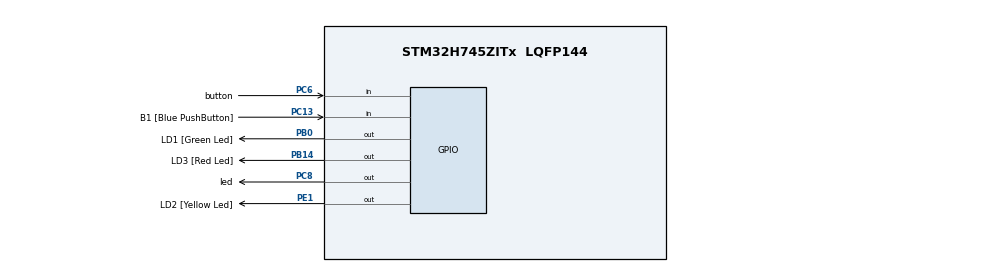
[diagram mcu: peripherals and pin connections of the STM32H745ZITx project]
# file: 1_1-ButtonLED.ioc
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CORTEX_M7.default_mode_Activation=1
CortexM4.IPs=FATFS_M4\:I,FREERTOS_M4\:I,IWDG2\:I,RCC,WWDG2\:I,DMA,BDMA,MDMA,NVIC2\:I,USART3,ETH,DEBUG,PDM2PCM_M4\:I,PWR,RESMGR_UTILITY,SYS_M4\:I,USB_DEVICE_M4\:I,USB_HOST_M4\:I,CORTEX_M4\:I,GPIO,OPENAMP_M4\:I,VREFBUF,NUCLEO-H745ZI-Q\:I
CortexM7.IPs=FATFS_M7\:I,FREERTOS_M7\:I,IWDG1\:I,RCC\:I,WWDG1\:I,DMA\:I,BDMA\:I,MDMA\:I,NVIC1\:I,SYS\:I,USART3\:I,USB_OTG_FS\:I,ETH\:I,CORTEX_M7\:I,DEBUG\:I,PDM2PCM_M7\:I,PWR\:I,RESMGR_UTILITY\:I,USB_DEVICE_M7\:I,USB_HOST_M7\:I,GPIO\:I,OPENAMP_M7\:I,VREFBUF\:I,MEMORYMAP\:I
CortexM7.Pins=PC6,PC8
Mcu.Family=STM32H7
Mcu.Name=STM32H745ZITx
Mcu.Package=LQFP144
NVIC1.PriorityGroup=NVIC_PRIORITYGROUP_4
NVIC2.PriorityGroup=NVIC_PRIORITYGROUP_4
PB0.GPIO_Label=LD1 [Green Led]
PB0.PinAttribute=Free
PB0.Signal=GPIO_Output
PB14.GPIO_Label=LD3 [Red Led]
PB14.PinAttribute=Free
PB14.Signal=GPIO_Output
PC13.GPIO_Label=B1 [Blue PushButton]
PC13.PinAttribute=Free
PC13.Signal=GPIO_Input
PC14-OSC32_IN\ (OSC32_IN).Mode=LSE-External-Oscillator
PC14-OSC32_IN\ (OSC32_IN).PinAttribute=Free
PC14-OSC32_IN\ (OSC32_IN).Signal=RCC_OSC32_IN
PC15-OSC32_OUT\ (OSC32_OUT).Mode=LSE-External-Oscillator
PC15-OSC32_OUT\ (OSC32_OUT).PinAttribute=Free
PC15-OSC32_OUT\ (OSC32_OUT).Signal=RCC_OSC32_OUT
PC6.GPIO_Label=button
PC6.PinAttribute=CortexM7
PC6.Signal=GPIO_Input
PC8.GPIO_Label=led
PC8.PinAttribute=CortexM7
PC8.Signal=GPIO_Output
PD8.GPIO_Label=STLINK_RX
PD8.PinAttribute=CortexM7
PD8.Signal=USART3_TX
PD9.GPIO_Label=STLINK_TX
PD9.PinAttribute=CortexM7
PD9.Signal=USART3_RX
PE1.GPIO_Label=LD2 [Yellow Led]
PE1.PinAttribute=Free
PE1.Signal=GPIO_Output
PH0-OSC_IN\ (PH0).Mode=HSE-External-Oscillator
PH0-OSC_IN\ (PH0).PinAttribute=Free
PH0-OSC_IN\ (PH0).Signal=RCC_OSC_IN
PH1-OSC_OUT\ (PH1).Mode=HSE-External-Oscillator
PH1-OSC_OUT\ (PH1).PinAttribute=Free
PH1-OSC_OUT\ (PH1).Signal=RCC_OSC_OUT
ProjectManager.HeapSize=M4-0x200,M7-0x200
ProjectManager.StackSize=M4-0x400,M7-0x400
ProjectManager.TargetToolchain=STM32CubeIDE
RCC.ADCFreq_Value=129000000
RCC.APB1Freq_Value=120000000
RCC.APB2Freq_Value=120000000
RCC.APB3Freq_Value=120000000
RCC.APB4Freq_Value=120000000
RCC.CortexFreq_Value=480000000
RCC.D1PPRE=RCC_APB3_DIV2
RCC.D2PPRE1=RCC_APB1_DIV2
RCC.D2PPRE2=RCC_APB2_DIV2
RCC.D3PPRE=RCC_APB4_DIV2
RCC.DIVM1=4
RCC.DIVM3=22
RCC.DIVN1=60
RCC.DIVN3=169
RCC.DIVQ3=4
RCC.HCLKFreq_Value=240000000
RCC.HPRE=RCC_HCLK_DIV2
RCC.PLL2FRACN=0
RCC.PLL3FRACN=0
RCC.PLLFRACN=0
RCC.SYSCLKFreq_VALUE=480000000
RCC.SYSCLKSource=RCC_SYSCLKSOURCE_PLLCLK
RCC.SupplySource=PWR_LDO_SUPPLY
RCC.USBCLockSelection=RCC_USBCLKSOURCE_PLL3
RCC.USBFreq_Value=122909090.9090909
VP_MEMORYMAP_VS_MEMORYMAP.Mode=CurAppReg
VP_SYS_M4_VS_Systick.Mode=SysTick
board=NUCLEO-H745ZI-Q

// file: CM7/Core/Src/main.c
/* USER CODE BEGIN Header */
/**
  ******************************************************************************
  * @file           : main.c
  * @brief          : Main program body
  ******************************************************************************
  * @attention
  *
  * Copyright (c) 2025 STMicroelectronics.
  * All rights reserved.
  *
  * This software is licensed under terms that can be found in the LICENSE file
  * in the root directory of this software component.
  * If no LICENSE file comes with this software, it is provided AS-IS.
  *
  ******************************************************************************
  */
/* USER CODE END Header */
#include "main.h"

/* USER CODE BEGIN PD */

/* DUAL_CORE_BOOT_SYNC_SEQUENCE: Define for dual core boot synchronization    */
/*                             demonstration code based on hardware semaphore */
/* This define is present in both CM7/CM4 projects                            */
/* To comment when developping/debugging on a single core                     */
#define DUAL_CORE_BOOT_SYNC_SEQUENCE

#if defined(DUAL_CORE_BOOT_SYNC_SEQUENCE)
#ifndef HSEM_ID_0
#define HSEM_ID_0 (0U) /* HW semaphore 0*/
#endif
#endif /* DUAL_CORE_BOOT_SYNC_SEQUENCE */

/* USER CODE END PD */

void SystemClock_Config(void);
static void MPU_Config(void);
static void MX_GPIO_Init(void);

int main(void)
{

/* USER CODE BEGIN Boot_Mode_Sequence_0 */
#if defined(DUAL_CORE_BOOT_SYNC_SEQUENCE)
  int32_t timeout;
#endif /* DUAL_CORE_BOOT_SYNC_SEQUENCE */
/* USER CODE END Boot_Mode_Sequence_0 */

  /* MPU Configuration--------------------------------------------------------*/
  MPU_Config();

/* USER CODE BEGIN Boot_Mode_Sequence_1 */
#if defined(DUAL_CORE_BOOT_SYNC_SEQUENCE)
  /* Wait until CPU2 boots and enters in stop mode or timeout*/
  timeout = 0xFFFF;
  while((__HAL_RCC_GET_FLAG(RCC_FLAG_D2CKRDY) != RESET) && (timeout-- > 0));
  if ( timeout < 0 )
  {
  Error_Handler();
  }
#endif /* DUAL_CORE_BOOT_SYNC_SEQUENCE */
/* USER CODE END Boot_Mode_Sequence_1 */
  /* MCU Configuration--------------------------------------------------------*/

  /* Reset of all peripherals, Initializes the Flash interface and the Systick. */
  HAL_Init();

  /* Configure the system clock */
  SystemClock_Config();
/* USER CODE BEGIN Boot_Mode_Sequence_2 */
#if defined(DUAL_CORE_BOOT_SYNC_SEQUENCE)
/* When system initialization is finished, Cortex-M7 will release Cortex-M4 by means of
HSEM notification */
/*HW semaphore Clock enable*/
__HAL_RCC_HSEM_CLK_ENABLE();
/*Take HSEM */
HAL_HSEM_FastTake(HSEM_ID_0);
/*Release HSEM in order to notify the CPU2(CM4)*/
HAL_HSEM_Release(HSEM_ID_0,0);
/* wait until CPU2 wakes up from stop mode */
timeout = 0xFFFF;
while((__HAL_RCC_GET_FLAG(RCC_FLAG_D2CKRDY) == RESET) && (timeout-- > 0));
if ( timeout < 0 )
{
Error_Handler();
}
#endif /* DUAL_CORE_BOOT_SYNC_SEQUENCE */
/* USER CODE END Boot_Mode_Sequence_2 */

  /* Initialize all configured peripherals */
  MX_GPIO_Init();

  /* Infinite loop */
  while (1)
  {

    /* USER CODE BEGIN 3 */
	  HAL_GPIO_WritePin(led_GPIO_Port, led_Pin, GPIO_PIN_RESET);

//	  if(HAL_GPIO_ReadPin(button_GPIO_Port, button_Pin) == 1){
//		  HAL_GPIO_WritePin(led_GPIO_Port, led_Pin, GPIO_PIN_SET);
//	  }
  }
  /* USER CODE END 3 */
}

void SystemClock_Config(void)
{
  RCC_OscInitTypeDef RCC_OscInitStruct = {0};
  RCC_ClkInitTypeDef RCC_ClkInitStruct = {0};

  /** Supply configuration update enable
  */
  HAL_PWREx_ConfigSupply(PWR_LDO_SUPPLY);

  /** Configure the main internal regulator output voltage
  */
  __HAL_PWR_VOLTAGESCALING_CONFIG(PWR_REGULATOR_VOLTAGE_SCALE0);

  while(!__HAL_PWR_GET_FLAG(PWR_FLAG_VOSRDY)) {}

  /** Initializes the RCC Oscillators according to the specified parameters
  * in the RCC_OscInitTypeDef structure.
  */
  RCC_OscInitStruct.OscillatorType = RCC_OSCILLATORTYPE_HSI;
  RCC_OscInitStruct.HSIState = RCC_HSI_DIV1;
  RCC_OscInitStruct.HSICalibrationValue = RCC_HSICALIBRATION_DEFAULT;
  RCC_OscInitStruct.PLL.PLLState = RCC_PLL_ON;
  RCC_OscInitStruct.PLL.PLLSource = RCC_PLLSOURCE_HSI;
  RCC_OscInitStruct.PLL.PLLM = 4;
  RCC_OscInitStruct.PLL.PLLN = 60;
  RCC_OscInitStruct.PLL.PLLP = 2;
  RCC_OscInitStruct.PLL.PLLQ = 2;
  RCC_OscInitStruct.PLL.PLLR = 2;
  RCC_OscInitStruct.PLL.PLLRGE = RCC_PLL1VCIRANGE_3;
  RCC_OscInitStruct.PLL.PLLVCOSEL = RCC_PLL1VCOWIDE;
  RCC_OscInitStruct.PLL.PLLFRACN = 0;
  if (HAL_RCC_OscConfig(&RCC_OscInitStruct) != HAL_OK)
  {
    Error_Handler();
  }

  /** Initializes the CPU, AHB and APB buses clocks
  */
  RCC_ClkInitStruct.ClockType = RCC_CLOCKTYPE_HCLK|RCC_CLOCKTYPE_SYSCLK
                              |RCC_CLOCKTYPE_PCLK1|RCC_CLOCKTYPE_PCLK2
                              |RCC_CLOCKTYPE_D3PCLK1|RCC_CLOCKTYPE_D1PCLK1;
  RCC_ClkInitStruct.SYSCLKSource = RCC_SYSCLKSOURCE_PLLCLK;
  RCC_ClkInitStruct.SYSCLKDivider = RCC_SYSCLK_DIV1;
  RCC_ClkInitStruct.AHBCLKDivider = RCC_HCLK_DIV2;
  RCC_ClkInitStruct.APB3CLKDivider = RCC_APB3_DIV2;
  RCC_ClkInitStruct.APB1CLKDivider = RCC_APB1_DIV2;
  RCC_ClkInitStruct.APB2CLKDivider = RCC_APB2_DIV2;
  RCC_ClkInitStruct.APB4CLKDivider = RCC_APB4_DIV2;

  if (HAL_RCC_ClockConfig(&RCC_ClkInitStruct, FLASH_LATENCY_4) != HAL_OK)
  {
    Error_Handler();
  }
}

static void MX_GPIO_Init(void)
{
  GPIO_InitTypeDef GPIO_InitStruct = {0};

  /* GPIO Ports Clock Enable */
  __HAL_RCC_GPIOD_CLK_ENABLE();
  __HAL_RCC_GPIOC_CLK_ENABLE();

  /*Configure GPIO pin Output Level */
  HAL_GPIO_WritePin(led_GPIO_Port, led_Pin, GPIO_PIN_RESET);

  /*Configure GPIO pins : PD8 PD9 */
  GPIO_InitStruct.Pin = GPIO_PIN_8|GPIO_PIN_9;
  GPIO_InitStruct.Mode = GPIO_MODE_AF_PP;
  GPIO_InitStruct.Pull = GPIO_NOPULL;
  GPIO_InitStruct.Speed = GPIO_SPEED_FREQ_LOW;
  GPIO_InitStruct.Alternate = GPIO_AF7_USART3;
  HAL_GPIO_Init(GPIOD, &GPIO_InitStruct);

  /*Configure GPIO pin : button_Pin */
  GPIO_InitStruct.Pin = button_Pin;
  GPIO_InitStruct.Mode = GPIO_MODE_INPUT;
  GPIO_InitStruct.Pull = GPIO_NOPULL;
  HAL_GPIO_Init(button_GPIO_Port, &GPIO_InitStruct);

  /*Configure GPIO pin : led_Pin */
  GPIO_InitStruct.Pin = led_Pin;
  GPIO_InitStruct.Mode = GPIO_MODE_OUTPUT_PP;
  GPIO_InitStruct.Pull = GPIO_NOPULL;
  GPIO_InitStruct.Speed = GPIO_SPEED_FREQ_LOW;
  HAL_GPIO_Init(led_GPIO_Port, &GPIO_InitStruct);

}

 /* MPU Configuration */

void MPU_Config(void)
{
  MPU_Region_InitTypeDef MPU_InitStruct = {0};

  /* Disables the MPU */
  HAL_MPU_Disable();

  /** Initializes and configures the Region and the memory to be protected
  */
  MPU_InitStruct.Enable = MPU_REGION_ENABLE;
  MPU_InitStruct.Number = MPU_REGION_NUMBER0;
  MPU_InitStruct.BaseAddress = 0x0;
  MPU_InitStruct.Size = MPU_REGION_SIZE_4GB;
  MPU_InitStruct.SubRegionDisable = 0x87;
  MPU_InitStruct.TypeExtField = MPU_TEX_LEVEL0;
  MPU_InitStruct.AccessPermission = MPU_REGION_NO_ACCESS;
  MPU_InitStruct.DisableExec = MPU_INSTRUCTION_ACCESS_DISABLE;
  MPU_InitStruct.IsShareable = MPU_ACCESS_SHAREABLE;
  MPU_InitStruct.IsCacheable = MPU_ACCESS_NOT_CACHEABLE;
  MPU_InitStruct.IsBufferable = MPU_ACCESS_NOT_BUFFERABLE;

  HAL_MPU_ConfigRegion(&MPU_InitStruct);
  /* Enables the MPU */
  HAL_MPU_Enable(MPU_PRIVILEGED_DEFAULT);

}

void Error_Handler(void)
{
  __disable_irq();
  while (1)
  {
  }
}
